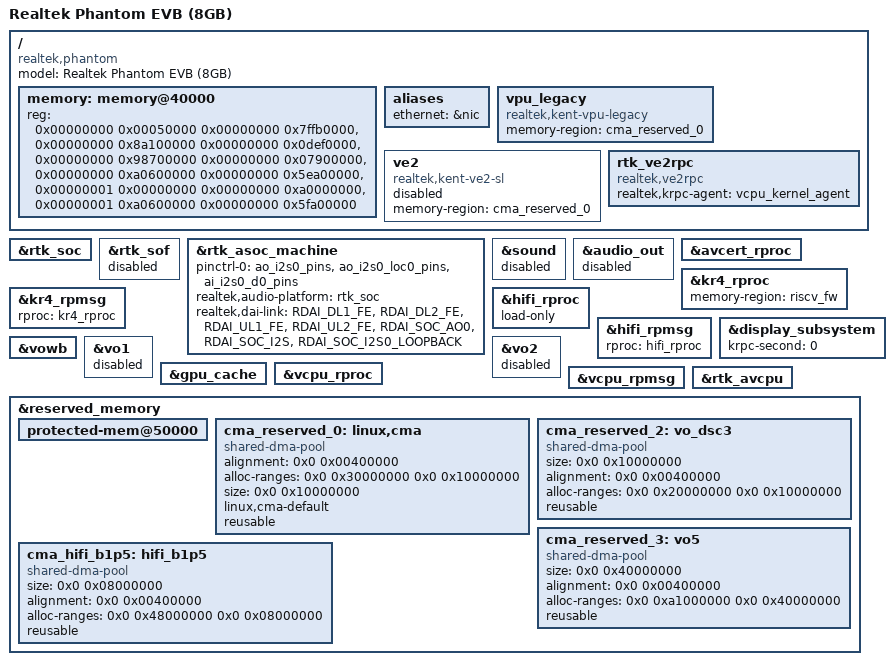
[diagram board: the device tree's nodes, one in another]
// SPDX-License-Identifier: (GPL-2.0-or-later OR BSD-2-Clause)
/*
 * Realtek RTD1501S Phantom EVB
 *
 * Copyright (c) 2024 Realtek Semiconductor Corp.
 */

/dts-v1/;

#include "rtd1501s-phantom.dtsi"

/ {
	compatible = "realtek,phantom", "realtek,rtd1501s";
	model = "Realtek Phantom EVB (8GB)";

	memory: memory@40000 {
		device_type = "memory";
		reg = <0x00000000 0x00050000 0x00000000 0x7ffb0000>,
		      <0x00000000 0x8a100000 0x00000000 0x0def0000>,
		      <0x00000000 0x98700000 0x00000000 0x07900000>,
		      <0x00000000 0xa0600000 0x00000000 0x5ea00000>,
		      <0x00000001 0x00000000 0x00000000 0xa0000000>,
		      <0x00000001 0xa0600000 0x00000000 0x5fa00000>;
	};

	aliases {
		ethernet = &nic;
	};

	vpu_legacy: vpu_legacy {
		compatible = "realtek,kent-vpu-legacy";
		memory-region=<&cma_reserved_0>;
		status = "disabled";
	};

	ve2: ve2 {
		compatible = "realtek,kent-ve2-sl";
		memory-region=<&cma_reserved_0>;
		status = "disabled";
	};

	rtk_ve2rpc: rtk_ve2rpc {
		compatible = "realtek,ve2rpc";
		realtek,krpc-agent = <&vcpu_kernel_agent>;
	};
};

&rtk_soc {
	status = "okay";
};

&rtk_sof {
	status = "disabled";
};

&rtk_asoc_machine {
	pinctrl-names = "default";
	pinctrl-0 =  <&ao_i2s0_pins>, <&ao_i2s0_loc0_pins>, <&ai_i2s0_d0_pins>;
	realtek,audio-platform = <&rtk_soc>;
	realtek,dai-link = "RDAI_DL1_FE", "RDAI_DL2_FE", "RDAI_UL1_FE", "RDAI_UL2_FE",
						"RDAI_SOC_AO0", "RDAI_SOC_I2S", "RDAI_SOC_I2S0_LOOPBACK";
	status = "okay";
};

&sound {
	status = "disabled";
};

&audio_out {
	status = "disabled";
};

&avcert_rproc {
	status = "okay";
};

&kr4_rproc {
	memory-region = <&riscv_fw>;
	status = "okay";
};

&kr4_rpmsg {
	rproc = <&kr4_rproc>;
	status = "okay";
};

&hifi_rproc {
	load-only;
	status = "okay";
};

&hifi_rpmsg {
	/delete-property/ skip-handshake;
	rproc = <&hifi_rproc>;
	status = "okay";
};

&display_subsystem {
	status = "okay";
	krpc-second = <0>;
};

&vowb {
	status = "okay";
};

&vo1 {
	status = "disabled";
};

&vo2 {
	status = "disabled";
};

&gpu_cache {
	status = "okay";
};

&vpu_legacy {
	status = "okay";
};

&vcpu_rproc {
	status = "okay";
};

&vcpu_rpmsg {
	status = "okay";
};

&rtk_avcpu {
	status = "okay";
};

&reserved_memory {
	protected-mem@50000 {
		status = "okay";
	};

	cma_reserved_0:linux,cma {
		compatible = "shared-dma-pool";
		alignment = <0x0 0x00400000>;
		/* Avoid crossing A/VCPU PA2VA per 512M boundary */
		/* Avoid allocating 0x1fc00000 ~ 0x1fc00fff to LX CPU (A/VCPU/VE3) */
		alloc-ranges=<0x0 0x30000000 0x0 0x10000000>;
		size = <0x0 0x10000000>; /* 256M */
		linux,cma-default;
		reusable;
	};

	cma_reserved_2:vo_dsc3 {
		compatible = "shared-dma-pool";
		size = <0x0 0x10000000>;            /* 256M */
		alignment = <0x0 0x00400000>;
		/* Avoid crossing A/VCPU PA2VA per 512M boundary */
		/* Avoid allocating 0x1fc00000 ~ 0x1fc00fff to LX CPU (A/VCPU/VE3) */
		alloc-ranges=<0x0 0x20000000 0x0 0x10000000>;
		reusable;
	};

	cma_reserved_3:vo5 {
		compatible = "shared-dma-pool";
		size = <0x0 0x40000000>;            /* 1024M */
		alignment = <0x0 0x00400000>;
		/* Avoid crossing A/VCPU PA2VA per 512M boundary */
		/* Avoid allocating 0x1fc00000 ~ 0x1fc00fff to LX CPU (A/VCPU/VE3) */
		alloc-ranges=<0x0 0xa1000000 0x0 0x40000000>;
		reusable;
	};

	cma_hifi_b1p5:hifi_b1p5 {
		compatible = "shared-dma-pool";
		size = <0x0 0x08000000>;            /* 128M */
		alignment = <0x0 0x00400000>;
		alloc-ranges=<0x0 0x48000000 0x0 0x08000000>;
		reusable;
	};
	/delete-node/linux,cma_1;
	/delete-node/linux,cma_2;
};

